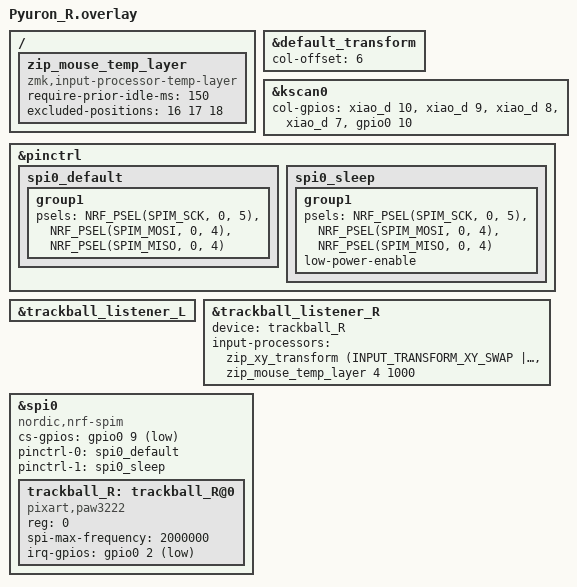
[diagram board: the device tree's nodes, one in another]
#include <zephyr/dt-bindings/input/input-event-codes.h>
#include <dt-bindings/zmk/input_transform.h>
#include <input/processors.dtsi>
#include <dt-bindings/zmk/bt.h>
#include "Pyuron.dtsi"

&default_transform {
    col-offset = <6>;
};

&kscan0 {
    col-gpios = <&xiao_d 10 GPIO_ACTIVE_HIGH>,
                <&xiao_d 9 GPIO_ACTIVE_HIGH>,
                <&xiao_d 8 GPIO_ACTIVE_HIGH>,
                <&xiao_d 7 GPIO_ACTIVE_HIGH>,
                <&gpio0 10 GPIO_ACTIVE_HIGH>;
};

&pinctrl {
    spi0_default: spi0_default {
        group1 {
            psels = <NRF_PSEL(SPIM_SCK, 0, 5)>,
                    <NRF_PSEL(SPIM_MOSI, 0, 4)>,
                    <NRF_PSEL(SPIM_MISO, 0, 4)>;
        };
    };

    spi0_sleep: spi0_sleep {
        group1 {
            psels = <NRF_PSEL(SPIM_SCK, 0, 5)>,
                    <NRF_PSEL(SPIM_MOSI, 0, 4)>,
                    <NRF_PSEL(SPIM_MISO, 0, 4)>;
            low-power-enable;
        };
    };
};

/ {
    /* Enables layer 4 (MOUSE) automatically while the right
     * trackball (pointer) is moving, and turns it off 1000ms
     * after movement stops (see the timeout argument below).
     * The mouse-button positions on layer 4
     * (J/K/L = MB1/MB3/MB2 = positions 16/17/18) are excluded so
     * clicking does not immediately drop the layer.
     *
     * The 1000ms timeout cuts both ways: it is short enough that
     * "move -> pause -> click" can fall out of the layer, and long
     * enough that a `k` typed right after moving becomes a middle
     * click. The manual path for the first case is Enter-hold
     * (layer FUNC), which puts the same buttons at 16/17/18.
     *
     * require-prior-idle-ms keeps the layer from engaging when the
     * ball is brushed mid-typing; 150 matches the home-row mods.
     */
    zip_mouse_temp_layer: zip_mouse_temp_layer {
        compatible = "zmk,input-processor-temp-layer";
        #input-processor-cells = <2>;
        require-prior-idle-ms = <150>;
        excluded-positions = <16 17 18>;
    };
};

&trackball_listener_L {
    status = "okay";
};

&trackball_listener_R {
    status = "okay";
    device = <&trackball_R>;
    input-processors =
        <&zip_xy_transform (INPUT_TRANSFORM_XY_SWAP | INPUT_TRANSFORM_Y_INVERT)>,
        <&zip_mouse_temp_layer 4 1000>;
};

&spi0 {
    status = "okay";
    cs-gpios = <&gpio0 9 GPIO_ACTIVE_LOW>;
    pinctrl-0 = <&spi0_default>;
    pinctrl-1 = <&spi0_sleep>;
    pinctrl-names = "default", "sleep";
    compatible = "nordic,nrf-spim";

    trackball_R: trackball_R@0 {
        status = "okay";
        compatible = "pixart,paw3222";
        reg = <0>;
        spi-max-frequency = <2000000>;
        irq-gpios = <&gpio0 2 (GPIO_ACTIVE_LOW | GPIO_PULL_UP)>;
    };
};
